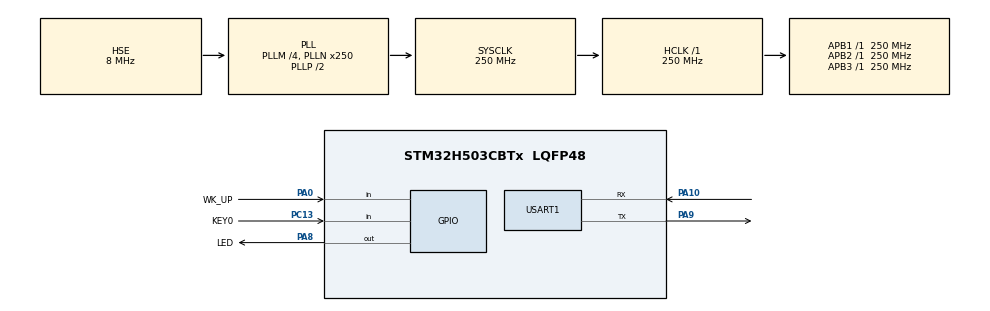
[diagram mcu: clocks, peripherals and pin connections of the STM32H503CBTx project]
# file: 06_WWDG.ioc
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BOOTPATH.BootPathName=LEGACY
BOOTPATH.UserSelectedBootPath=LEGACY
Mcu.Family=STM32H5
Mcu.Name=STM32H503CBTx
Mcu.Package=LQFP48
NVIC.PriorityGroup=NVIC_PRIORITYGROUP_2
NVIC.USART1_IRQn=true\:2\:2\:true\:false\:true\:true\:true\:true
NVIC.WWDG_IRQn=true\:2\:1\:true\:false\:true\:true\:true\:true
PA0.GPIO_Label=WK_UP
PA0.GPIO_PuPd=GPIO_PULLDOWN
PA0.Signal=GPIO_Input
PA10.GPIO_ModeDefaultPP=GPIO_MODE_AF_PP
PA10.GPIO_Speed=GPIO_SPEED_FREQ_LOW
PA10.Mode=Asynchronous
PA10.Signal=USART1_RX
PA8.GPIO_Label=LED
PA8.GPIO_ModeDefaultOutputPP=GPIO_MODE_OUTPUT_PP
PA8.GPIO_PuPd=GPIO_PULLUP
PA8.PinState=GPIO_PIN_SET
PA8.Signal=GPIO_Output
PA9.GPIO_Speed=GPIO_SPEED_FREQ_HIGH
PA9.Mode=Asynchronous
PA9.Signal=USART1_TX
PC13.GPIO_Label=KEY0
PC13.GPIO_PuPd=GPIO_PULLDOWN
PC13.Signal=GPIO_Input
PC14-OSC32_IN(OSC32_IN).Mode=LSE-External-Oscillator
PC14-OSC32_IN(OSC32_IN).Signal=RCC_OSC32_IN
PC15-OSC32_OUT(OSC32_OUT).Mode=LSE-External-Oscillator
PC15-OSC32_OUT(OSC32_OUT).Signal=RCC_OSC32_OUT
PH0-OSC_IN(PH0).Mode=HSE-External-Oscillator
PH0-OSC_IN(PH0).Signal=RCC_OSC_IN
PH1-OSC_OUT(PH1).Mode=HSE-External-Oscillator
PH1-OSC_OUT(PH1).Signal=RCC_OSC_OUT
ProjectManager.HeapSize=0x200
ProjectManager.StackSize=0x400
ProjectManager.TargetToolchain=STM32CubeIDE
RCC.ADCFreq_Value=250000000
RCC.AHBFreq_Value=250000000
RCC.APB1Freq_Value=250000000
RCC.APB1TimFreq_Value=250000000
RCC.APB2Freq_Value=250000000
RCC.APB2TimFreq_Value=250000000
RCC.APB3Freq_Value=250000000
RCC.CSI_VALUE=4000000
RCC.CortexFreq_Value=250000000
RCC.EPOD_VALUE=8000000
RCC.HCLKFreq_Value=250000000
RCC.HSE_VALUE=8000000
RCC.HSI48_VALUE=48000000
RCC.HSI_VALUE=64000000
RCC.LSIRC_VALUE=32000
RCC.PLLM=4
RCC.PLLN=250
RCC.PLLSourceVirtual=RCC_PLL1_SOURCE_HSE
RCC.SYSCLKFreq_VALUE=250000000
RCC.SYSCLKSource=RCC_SYSCLKSOURCE_PLLCLK
RCC.USBFreq_Value=48000000
RCC.VCOOutputFreq_Value=500000000
USART1.VirtualMode=VM_ASYNC
VP_BOOTPATH_VS_BOOTPATH.Mode=BP_Activate
VP_ICACHE_VS_ICACHE.Mode=DefaultMode
VP_MEMORYMAP_VS_MEMORYMAP.Mode=CurAppReg
VP_PWR_VS_DBSignals.Mode=DisableDeadBatterySignals
VP_PWR_VS_LPOM.Mode=PowerOptimisation
VP_PWR_VS_SECSignals.Mode=Security/Privilege
VP_WWDG_VS_WWDG.Mode=WWDG_Activate
WWDG.Counter=0x7F
WWDG.EWIMode=WWDG_EWI_ENABLE
WWDG.Prescaler=WWDG_PRESCALER_8
WWDG.Window=0x5F
board=custom

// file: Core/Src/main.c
/**
 ****************************************************************************************************
 * @file        main.c
 * @author      ALIENTEK
 * @brief       WWDG code
 * @license     Copyright (C) 2012-2024, ALIENTEK
 ****************************************************************************************************
 * @attention
 *
 * platform     : ALIENTEK M48-STM32H503 board
 * website      : www.alientek.com
 * forum        : www.openedv.com/forum.php
 *
 * change logs  ：
 * version      data         notes
 * V1.0         20240309     the first version
 *
 ****************************************************************************************************
 */

/* USER CODE BEGIN Header */

/* USER CODE END Header */
#include "main.h"
#include "icache.h"
#include "memorymap.h"
#include "usart.h"
#include "wwdg.h"
#include "gpio.h"

/* USER CODE BEGIN Includes */
#include "../../BSP/LED/led.h"
#include "../../BSP/KEY/key.h"
/* USER CODE END Includes */

void SystemClock_Config(void);

/* USER CODE BEGIN 0 */
/**
 * @brief   Displays information about the experiment
 * @param   None
 * @retval  None
 */
void stm32h503cb_show_mesg(void)
{
	/* The serial port outputs the experimental information */
	printf("\n");
	printf("********************************\r\n");
	printf("STM32H503\r\n");
	printf("WWDG Test\r\n");
	printf("ATOM@ALIENTEK\r\n");
	printf("********************************\r\n");
	printf("\r\n");
}
/* USER CODE END 0 */

int main(void)
{

  /* MCU Configuration--------------------------------------------------------*/

  /* Reset of all peripherals, Initializes the Flash interface and the Systick. */
  HAL_Init();

  /* Configure the system clock */
  SystemClock_Config();

  /* Initialize all configured peripherals */
  MX_GPIO_Init();
  MX_ICACHE_Init();
  MX_USART1_UART_Init();
  MX_WWDG_Init();
  /* USER CODE BEGIN 2 */
  LED(0);                    /* turn on LED */
  HAL_Delay(300);   		 /* delay 300ms */
  stm32h503cb_show_mesg();
  /* USER CODE END 2 */

  /* Infinite loop */
  /* USER CODE BEGIN WHILE */
  while (1)
  {
	  LED(1);               /* turn off LED */
    /* USER CODE END WHILE */

  }
}

void SystemClock_Config(void)
{
  RCC_OscInitTypeDef RCC_OscInitStruct = {0};
  RCC_ClkInitTypeDef RCC_ClkInitStruct = {0};

  /** Configure the main internal regulator output voltage
  */
  __HAL_PWR_VOLTAGESCALING_CONFIG(PWR_REGULATOR_VOLTAGE_SCALE0);

  while(!__HAL_PWR_GET_FLAG(PWR_FLAG_VOSRDY)) {}

  /** Initializes the RCC Oscillators according to the specified parameters
  * in the RCC_OscInitTypeDef structure.
  */
  RCC_OscInitStruct.OscillatorType = RCC_OSCILLATORTYPE_HSE;
  RCC_OscInitStruct.HSEState = RCC_HSE_ON;
  RCC_OscInitStruct.PLL.PLLState = RCC_PLL_ON;
  RCC_OscInitStruct.PLL.PLLSource = RCC_PLL1_SOURCE_HSE;
  RCC_OscInitStruct.PLL.PLLM = 4;
  RCC_OscInitStruct.PLL.PLLN = 250;
  RCC_OscInitStruct.PLL.PLLP = 2;
  RCC_OscInitStruct.PLL.PLLQ = 2;
  RCC_OscInitStruct.PLL.PLLR = 2;
  RCC_OscInitStruct.PLL.PLLRGE = RCC_PLL1_VCIRANGE_1;
  RCC_OscInitStruct.PLL.PLLVCOSEL = RCC_PLL1_VCORANGE_WIDE;
  RCC_OscInitStruct.PLL.PLLFRACN = 0;
  if (HAL_RCC_OscConfig(&RCC_OscInitStruct) != HAL_OK)
  {
    Error_Handler();
  }

  /** Initializes the CPU, AHB and APB buses clocks
  */
  RCC_ClkInitStruct.ClockType = RCC_CLOCKTYPE_HCLK|RCC_CLOCKTYPE_SYSCLK
                              |RCC_CLOCKTYPE_PCLK1|RCC_CLOCKTYPE_PCLK2
                              |RCC_CLOCKTYPE_PCLK3;
  RCC_ClkInitStruct.SYSCLKSource = RCC_SYSCLKSOURCE_PLLCLK;
  RCC_ClkInitStruct.AHBCLKDivider = RCC_SYSCLK_DIV1;
  RCC_ClkInitStruct.APB1CLKDivider = RCC_HCLK_DIV1;
  RCC_ClkInitStruct.APB2CLKDivider = RCC_HCLK_DIV1;
  RCC_ClkInitStruct.APB3CLKDivider = RCC_HCLK_DIV1;

  if (HAL_RCC_ClockConfig(&RCC_ClkInitStruct, FLASH_LATENCY_5) != HAL_OK)
  {
    Error_Handler();
  }
}

void Error_Handler(void)
{
  __disable_irq();
  while (1)
  {
  }
}
